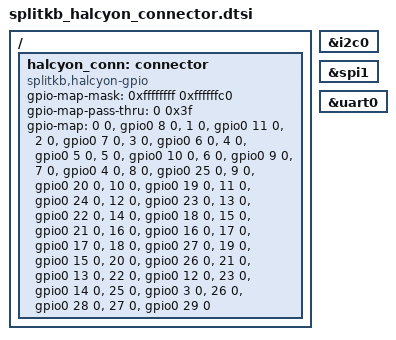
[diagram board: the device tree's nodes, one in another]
/*
 * Copyright (c) 2021 Peter Johanson
 *
 * SPDX-License-Identifier: Apache-2.0
 */

/ {
	halcyon_conn: connector {
		compatible = "splitkb,halcyon-gpio";
		#gpio-cells = <2>;
		gpio-map-mask = <0xffffffff 0xffffffc0>;
		gpio-map-pass-thru = <0 0x3f>;
		gpio-map
			= <0 0 &gpio0 8 0>
			, <1 0 &gpio0 11 0>
			, <2 0 &gpio0 7 0>
			, <3 0 &gpio0 6 0>
			, <4 0 &gpio0 5 0>
			, <5 0 &gpio0 10 0>
			, <6 0 &gpio0 9 0>
			, <7 0 &gpio0 4 0>
			, <8 0 &gpio0 25 0>
			, <9 0 &gpio0 20 0>
			, <10 0 &gpio0 19 0>
			, <11 0 &gpio0 24 0>
			, <12 0 &gpio0 23 0>
			, <13 0 &gpio0 22 0>
			, <14 0 &gpio0 18 0>
			, <15 0 &gpio0 21 0>
			/* VIK Pins on Halcyon Keyboard */
			, <16 0 &gpio0 16 0>
			, <17 0 &gpio0 17 0>
			/* VIK RGB Pin, in theory? */
			, <18 0 &gpio0 27 0>
			, <19 0 &gpio0 15 0>
			, <20 0 &gpio0 26 0>
			, <21 0 &gpio0 13 0>
			, <22 0 &gpio0 12 0>
			, <23 0 &gpio0 14 0>
			/* RGB */
			, <25 0 &gpio0 3 0>
			/* TX/RX */
			, <26 0 &gpio0 28 0>
			, <27 0 &gpio0 29 0>
			;
	};
};

halcyon_i2c: &i2c0 {};
halcyon_spi: &spi1 {};
halcyon_serial: &uart0 {};
